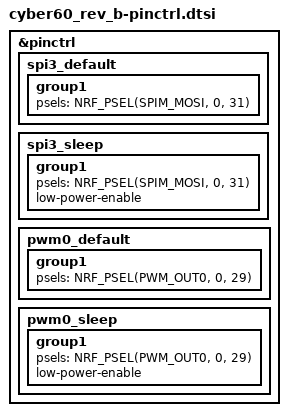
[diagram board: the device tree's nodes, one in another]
/*
 * Copyright (c) 2022 The ZMK Contributors
 * SPDX-License-Identifier: MIT
 */

&pinctrl {
    spi3_default: spi3_default {
        group1 {
            psels = <NRF_PSEL(SPIM_MOSI, 0, 31)>; // P0,31
        };
    };
    spi3_sleep: spi3_sleep {
        group1 {
            psels = <NRF_PSEL(SPIM_MOSI, 0, 31)>;
            low-power-enable;
        };
    };

    pwm0_default: pwm0_default {
        group1 {
            psels = <NRF_PSEL(PWM_OUT0, 0, 29)>;
        };
    };
    pwm0_sleep: pwm0_sleep {
        group1 {
            psels = <NRF_PSEL(PWM_OUT0, 0, 29)>;
            low-power-enable;
        };
    };
};
